# CYNTHION_SOC register map
Vendor: awtoau; File version: 1.0
Cynthion r1.4 VexiiRiscv SoC, generated from its Amaranth memory map
Registers are 8-bit, read-write, no defined reset value unless marked. A register's access mark holds for its fields unless they carry their own. Offsets are from the block's base; lines under a group give offsets from that group; [hi:lo] are bit positions; {n}, {i} and the like mark numbered series; 'fields as' and 'values as' point back to an identical list; <NAME> marks a mode.

## Memory map
0x00000000 RAM size 0x8000 — ram: 32768 bytes of memory at 0x00000000
0x10000000 SPIFLASH size 0x400000 — spiflash: 4194304 bytes of memory at 0x10000000
0xF0000000 CONSOLE size 0x8 — console: 8 registers at 0xf0000000
0xF0000100 FLASH size 0x80 — flash: 21 registers at 0xf0000100
0xF0000500 APOLLO_UART size 0x8 — apollo_uart: 8 registers at 0xf0000500
0xF0000600 BOARD_GPIO size 0x10 — board/gpio: 4 registers at 0xf0000600
0xF0000610 BOARD_I2C size 0x8 — board/i2c: 5 registers at 0xf0000610
0xF0000618 BOARD_SIDEBAND size 0x4 — board/sideband: 4 registers at 0xf0000618
0xF000061C BOARD_ULPI size 0x4 — board/ulpi: 4 registers at 0xf000061c
0xF0000620 BOARD_I2C_MUX size 0x2 — board/i2c_mux: 2 registers at 0xf0000620
0xF0000624 BOARD_VBUS size 0x4 — board/vbus: 1 register at 0xf0000624
0xF0000640 BOARD_FABRIC size 0x8 — board/fabric: 2 registers at 0xf0000640
0xF0000660 BOARD_CLOCKS size 0x10 — board/clocks: 2 registers at 0xf0000660
0xF0000800 HYPERRAM size 0x80 — hyperram: 41 registers at 0xf0000800
0xF0000C00 INTC size 0x8 — intc: 2 registers at 0xf0000c00
0xF0001000 USB_HOST size 0x20 — usb_host: 27 registers at 0xf0001000
0xF0010000 HYPERRAM_WINDOW size 0x1000 — hyperram_window: 4096 bytes of memory at 0xf0010000
0xF0011000 FLASH_BUF size 0x1000 — flash_buf: 4096 bytes of memory at 0xf0011000
0xF0800000 CLINT size 0x10000 — clint: 5 registers at 0xf0800000

## Interrupts
1 CONSOLE
2 APOLLO_UART
3 BOARD_I2C
4 BOARD_I2C_MUX_TARGET (BOARD_I2C_MUX)
5 BOARD_I2C_MUX_AUX (BOARD_I2C_MUX)
6 BOARD_I2C_MUX_POWER_ALERT (BOARD_I2C_MUX)
8 BOARD_I2C_MUX_TARGET_FAULT (BOARD_I2C_MUX)
9 BOARD_I2C_MUX_AUX_FAULT (BOARD_I2C_MUX)
10 USB_HOST
13 BOARD_GPIO_BUTTON (BOARD_GPIO)
17 BOARD_CLOCKS_PLL_LOSS (BOARD_CLOCKS)
18 HYPERRAM
19 FLASH

## CONSOLE — console: 8 registers at 0xf0000000
Base 0xF0000000
0x00 RBR_THR — CONSOLE.RBR_THR, 8 bits at +0x00
  [7:0] DATA — data [7:0]
0x01 IER — CONSOLE.IER, 8 bits at +0x01
  [7:0] DATA — data [7:0]
0x02 IIR_FCR — CONSOLE.IIR_FCR, 8 bits at +0x02
  [7:0] DATA — data [7:0]
0x03 LCR reset 0x0 — CONSOLE.LCR, 8 bits at +0x03
  [7:0] DATA — data [7:0]
0x04 MCR reset 0x0 — CONSOLE.MCR, 8 bits at +0x04
  [7:0] DATA — data [7:0]
0x05 LSR ro — CONSOLE.LSR, 8 bits at +0x05
  [7:0] DATA — data [7:0]
0x06 MSR ro — CONSOLE.MSR, 8 bits at +0x06
  [7:0] DATA — data [7:0]
0x07 SCR reset 0x0 — CONSOLE.SCR, 8 bits at +0x07
  [7:0] DATA — data [7:0]

## APOLLO_UART — apollo_uart: 8 registers at 0xf0000500
Base 0xF0000500
Registers as CONSOLE (with CONSOLE read as APOLLO_UART).

## FLASH — flash: 21 registers at 0xf0000100
Base 0xF0000100
0x00 ID 32-bit ro — FLASH.ID, 32 bits at +0x00
  [31:0] V — v [31:0]
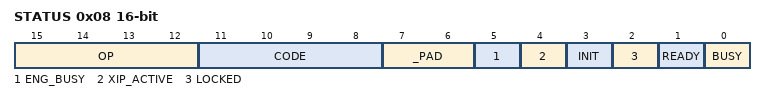
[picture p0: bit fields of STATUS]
0x08 STATUS 16-bit ro — FLASH.STATUS, 16 bits at +0x08
  [15:12] OP — op [15:12]
  [11:8] CODE — code [11:8]
  [7:6] _PAD — _pad [7:6]
  [5] ENG_BUSY — eng_busy [5]
  [4] XIP_ACTIVE — xip_active [4]
  [3] INIT — init [3]
  [2] LOCKED — locked [2]
  [1] READY — ready [1]
  [0] BUSY — busy [0]
0x0C CMD wo — FLASH.CMD, 4 bits at +0x0c
  [3:0] OP — op [3:0]
0x0D CTRL wo — FLASH.CTRL, 1 bits at +0x0d
  [0] ABORT — abort [0]
0x0E EVENTS reset 0x0 — FLASH.EVENTS, 2 bits at +0x0e
  [1:0] V — v [1:0]
0x0F IRQ_EN reset 0x0 — FLASH.IRQ_EN, 2 bits at +0x0f
  [1:0] V — v [1:0]
0x10 ERRORS 16-bit reset 0x0 — FLASH.ERRORS, 10 bits at +0x10
  [9:0] V — v [9:0]
0x14 ADDR 32-bit reset 0x0 — FLASH.ADDR, 22 bits at +0x14
  [21:0] V — v [21:0]
0x18 BUF_ADDR 16-bit reset 0x0 — FLASH.BUF_ADDR, 12 bits at +0x18
  [11:0] V — v [11:0]
0x1A LEN 16-bit reset 0x0 — FLASH.LEN, 13 bits at +0x1a
  [12:0] V — v [12:0]
0x1C RESULT 32-bit ro — FLASH.RESULT, 32 bits at +0x1c
  [31:0] V — v [31:0]
0x20 WRITE_LO 16-bit reset 0x0 — FLASH.WRITE_LO, 11 bits at +0x20
  [10:0] V — v [10:0]
0x22 WRITE_HI 16-bit reset 0x0 — FLASH.WRITE_HI, 11 bits at +0x22
  [10:0] V — v [10:0]
0x28 CAL_ADDR 32-bit reset 0x0 — FLASH.CAL_ADDR, 22 bits at +0x28
  [21:0] V — v [21:0]
0x2C CAL 32-bit ro — FLASH.CAL, 32 bits at +0x2c
  [31:0] V — v [31:0]
0x38 BUSY_CYCLES 32-bit ro — FLASH.BUSY_CYCLES, 29 bits at +0x38
  [28:0] V — v [28:0]
0x3C STATE 16-bit ro — FLASH.STATE, 16 bits at +0x3c
  [15:0] V — v [15:0]
0x3E SEQ 16-bit ro — FLASH.SEQ, 16 bits at +0x3e
  [15:0] V — v [15:0]
0x40 CK_COUNT 32-bit ro — FLASH.CK_COUNT, 22 bits at +0x40
  [21:0] V — v [21:0]
0x48 FILL_LAST 16-bit ro — FLASH.FILL_LAST, 16 bits at +0x48
  [15:0] V — v [15:0]
0x4A FILL_MAX 16-bit ro — FLASH.FILL_MAX, 16 bits at +0x4a
  [15:0] V — v [15:0]
